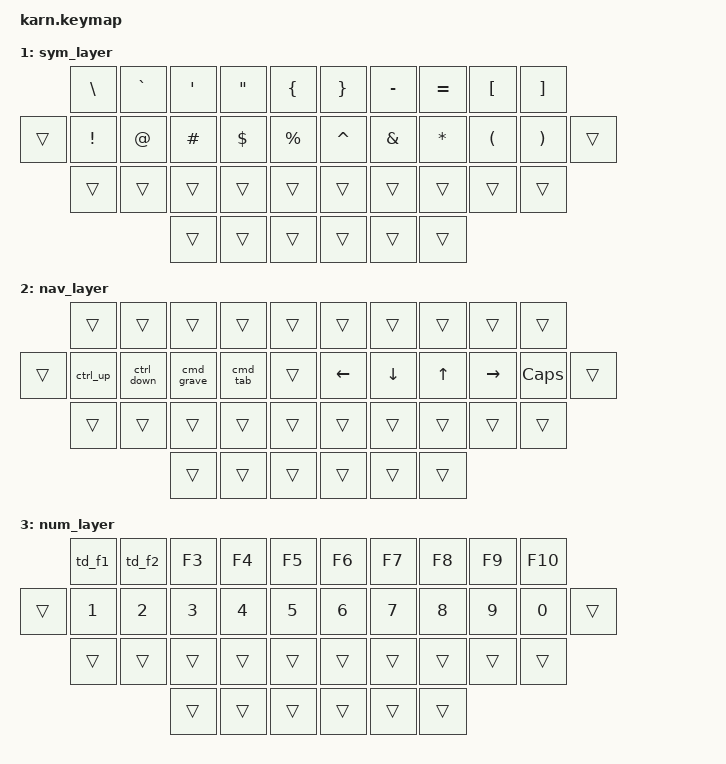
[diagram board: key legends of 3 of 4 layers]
#include <behaviors.dtsi>
#include <dt-bindings/zmk/keys.h>

#define DEFAULT 0
#define SYM     1 
#define NAV     2 
#define NUM     3 

#define MO_TOG(layer) &mo_tog layer layer   // Macro to apply momentary-layer-on-hold/toggle-layer-on-tap to a specific layer


/ {
    behaviors {
        mo_tog: behavior_mo_tog {
            compatible = "zmk,behavior-hold-tap";
            label = "mo_tog";
            #binding-cells = <2>;
            flavor = "hold-preferred";
            tapping-term-ms = <150>;
            bindings = <&mo>, <&tog>;
        };
        td_f1: tap_dance_f1 {
            compatible = "zmk,behavior-tap-dance";
            label = "tap_dance_f1";
            #binding-cells = <0>;
            tapping-term-ms = <200>;
            bindings = <&kp F1>, <&kp F11>;
        };
        td_f2: tap_dance_f2 {
            compatible = "zmk,behavior-tap-dance";
            label = "tap_dance_f2";
            #binding-cells = <0>;
            tapping-term-ms = <200>;
            bindings = <&kp F2>, <&kp F12>;
        };
    };

    macros {
        ctrl_up: ctrl_up {
            label = "ctrl_up";
            compatible = "zmk,behavior-macro";
            #binding-cells = <0>;
            bindings
                = <&macro_press &kp LCTRL>
                , <&macro_tap &kp UP>
                , <&macro_release &kp LCTRL>
                ;
        };
        ctrl_down: ctrl_down {
            label = "ctrl_down";
            compatible = "zmk,behavior-macro";
            #binding-cells = <0>;
            bindings
                = <&macro_press &kp LCTRL>
                , <&macro_tap &kp DOWN>
                , <&macro_release &kp LCTRL>
                ;
        };
        cmd_grave: cmd_grave {
            label = "cmd_grave";
            compatible = "zmk,behavior-macro";
            #binding-cells = <0>;
            bindings
                = <&macro_press &kp LCMD>
                , <&macro_tap &kp GRAVE>
                , <&macro_release &kp LCMD>
                ;
        };
        cmd_tab: cmd_tab {
            label = "cmd_tab";
            compatible = "zmk,behavior-macro";
            #binding-cells = <0>;
            bindings
                = <&macro_press &kp LCMD>
                , <&macro_tap &kp TAB>
                , <&macro_release &kp LCMD>
                ;
        };

    };

    keymap {
        compatible = "zmk,keymap";

        default_layer {
            bindings = <
            &kp Q &kp W &kp F &kp P   &kp G      &kp J    &kp L   &kp U     &kp Y   &kp ;
    &kp TAB &kp A &kp R &kp S &kp T   &kp D      &kp H    &kp N   &kp E     &kp I   &kp O    &kp ENT
            &kp Z &kp X &kp C &kp V   &kp B      &kp K    &kp M   &kp COMMA &kp DOT &kp FSLH
                        &mo 1 &kp ESC MO_TOG(3)  &kp BKSP &kp SPC MO_TOG(2)
            >;
        };

        sym_layer {
            bindings = <
            &kp BSLH &kp GRAVE &kp SQT  &kp DQT  &kp LBRC    &kp RBRC  &kp MINUS &kp EQUAL &kp LBKT &kp RBKT
    &trans  &kp EXCL &kp AT    &kp HASH &kp DLLR &kp PRCNT   &kp CARET &kp AMPS  &kp STAR  &kp LPAR &kp RPAR &trans
            &trans   &trans    &trans   &trans   &trans      &trans    &trans    &trans    &trans   &trans
                               &trans   &trans   &trans      &trans    &trans    &trans
            >;
        };

        nav_layer {
            bindings = <
            &trans   &trans     &trans     &trans   &trans      &trans   &trans   &trans  &trans    &trans
    &trans  &ctrl_up &ctrl_down &cmd_grave &cmd_tab &trans      &kp LEFT &kp DOWN &kp UP  &kp RIGHT &kp CAPS  &trans
            &trans   &trans     &trans     &trans   &trans      &trans   &trans   &trans  &trans    &trans
                                &trans     &trans   &trans      &trans   &trans   &trans
            >;
        };

        num_layer {
            bindings = <
            &td_f1 &td_f2 &kp F3 &kp F4 &kp F5   &kp F6 &kp F7 &kp F8 &kp F9 &kp F10
    &trans  &kp N1 &kp N2 &kp N3 &kp N4 &kp N5   &kp N6 &kp N7 &kp N8 &kp N9 &kp N0  &trans
            &trans &trans &trans &trans &trans   &trans &trans &trans &trans &trans
                          &trans &trans &trans   &trans &trans &trans
            >;
        };
    };
};
